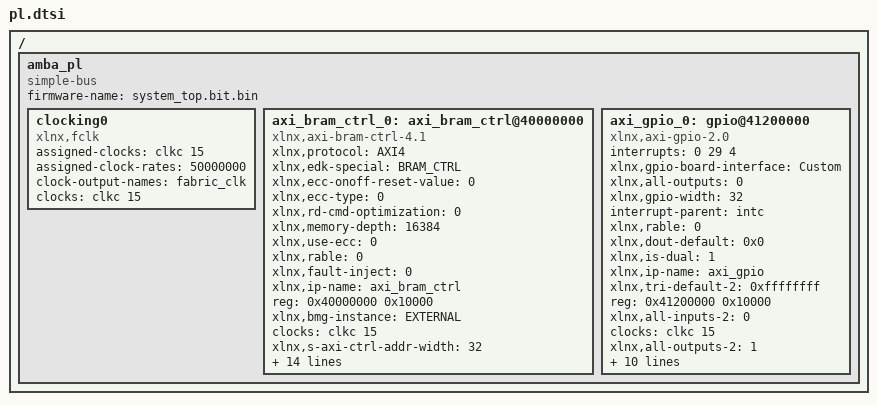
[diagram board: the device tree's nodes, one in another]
/ {
	amba_pl: amba_pl {
		ranges;
		compatible = "simple-bus";
		#address-cells = <1>;
		#size-cells = <1>;
		firmware-name = "system_top.bit.bin";
		clocking0: clocking0 {
			compatible = "xlnx,fclk";
			assigned-clocks = <&clkc 15>;
			assigned-clock-rates = <50000000>;
			#clock-cells = <0>;
			clock-output-names = "fabric_clk";
			clocks = <&clkc 15>;
		};
		axi_bram_ctrl_0: axi_bram_ctrl@40000000 {
			xlnx,protocol = "AXI4";
			xlnx,edk-special = "BRAM_CTRL";
			compatible = "xlnx,axi-bram-ctrl-4.1";
			xlnx,ecc-onoff-reset-value = <0>;
			xlnx,ecc-type = <0>;
			xlnx,rd-cmd-optimization = <0>;
			xlnx,memory-depth = <16384>;
			xlnx,use-ecc = <0>;
			xlnx,rable = <0>;
			xlnx,fault-inject = <0>;
			xlnx,ip-name = "axi_bram_ctrl";
			reg = <0x40000000 0x10000>;
			xlnx,bmg-instance = "EXTERNAL";
			clocks = <&clkc 15>;
			xlnx,s-axi-ctrl-addr-width = <32>;
			xlnx,read-latency = <1>;
			xlnx,id-width = <0>;
			xlnx,s-axi-supports-narrow-burst = <0>;
			xlnx,supports-narrow-burst = <0>;
			xlnx,single-port-bram = <1>;
			xlnx,ecc = <0>;
			xlnx,edk-iptype = "PERIPHERAL";
			status = "okay";
			clock-names = "s_axi_aclk";
			xlnx,data-width = <32>;
			xlnx,bram-addr-width = <14>;
			xlnx,bram-inst-mode = "EXTERNAL";
			xlnx,s-axi-ctrl-data-width = <32>;
			xlnx,mem-depth = <16384>;
			xlnx,s-axi-id-width = <1>;
			xlnx,name = "axi_bram_ctrl_0";
		};
		axi_gpio_0: gpio@41200000 {
			#interrupt-cells = <2>;
			interrupts = < 0 29 4 >;
			xlnx,gpio-board-interface = "Custom";
			compatible = "xlnx,axi-gpio-2.0" , "xlnx,xps-gpio-1.00.a";
			xlnx,all-outputs = <0>;
			#gpio-cells = <2>;
			xlnx,gpio-width = <32>;
			interrupt-parent = <&intc>;
			xlnx,rable = <0>;
			xlnx,dout-default = <0x0>;
			xlnx,is-dual = <1>;
			xlnx,ip-name = "axi_gpio";
			xlnx,tri-default-2 = <0xffffffff>;
			reg = <0x41200000 0x10000>;
			xlnx,all-inputs-2 = <0>;
			clocks = <&clkc 15>;
			xlnx,all-outputs-2 = <1>;
			gpio-controller;
			xlnx,interrupt-present = <1>;
			xlnx,gpio2-board-interface = "Custom";
			xlnx,edk-iptype = "PERIPHERAL";
			xlnx,dout-default-2 = <0x0>;
			status = "okay";
			xlnx,gpio2-width = <32>;
			clock-names = "s_axi_aclk";
			interrupt-controller;
			interrupt-names = "ip2intc_irpt";
			xlnx,tri-default = <0xffffffff>;
			xlnx,name = "axi_gpio_0";
			xlnx,all-inputs = <1>;
		};
	};
};
